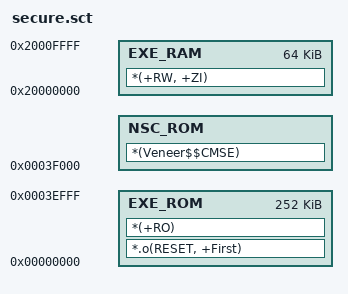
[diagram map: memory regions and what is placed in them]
LR_ROM 0x0
{
    EXE_ROM +0 0x3F000
    {
        *.o(RESET, +First)
        *(+RO)
    }
    
    EXE_RAM 0x20000000 0x10000
    {
        *(+RW, +ZI)
    }
}

LR_NSC 0x3F000
{
	NSC_ROM +0
	{
		*(Veneer$$CMSE)
	}
}

